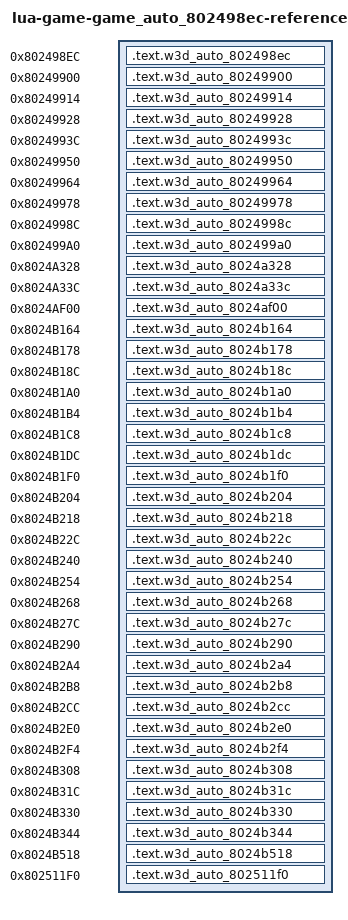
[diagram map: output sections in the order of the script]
/* Generated reference-only placements. All bodies are source-built. */
OUTPUT_FORMAT("elf32-powerpc")
OUTPUT_ARCH(powerpc)
ENTRY(w3d_auto_802498ec)
_SDA_BASE_ = 0x804b2540;
_SDA2_BASE_ = 0x804c2540;
SECTIONS {
  .text.w3d_auto_802498ec 0x802498ec : { *(.text.w3d_auto_802498ec) }
  .text.w3d_auto_80249900 0x80249900 : { *(.text.w3d_auto_80249900) }
  .text.w3d_auto_80249914 0x80249914 : { *(.text.w3d_auto_80249914) }
  .text.w3d_auto_80249928 0x80249928 : { *(.text.w3d_auto_80249928) }
  .text.w3d_auto_8024993c 0x8024993c : { *(.text.w3d_auto_8024993c) }
  .text.w3d_auto_80249950 0x80249950 : { *(.text.w3d_auto_80249950) }
  .text.w3d_auto_80249964 0x80249964 : { *(.text.w3d_auto_80249964) }
  .text.w3d_auto_80249978 0x80249978 : { *(.text.w3d_auto_80249978) }
  .text.w3d_auto_8024998c 0x8024998c : { *(.text.w3d_auto_8024998c) }
  .text.w3d_auto_802499a0 0x802499a0 : { *(.text.w3d_auto_802499a0) }
  .text.w3d_auto_8024a328 0x8024a328 : { *(.text.w3d_auto_8024a328) }
  .text.w3d_auto_8024a33c 0x8024a33c : { *(.text.w3d_auto_8024a33c) }
  .text.w3d_auto_8024af00 0x8024af00 : { *(.text.w3d_auto_8024af00) }
  .text.w3d_auto_8024b164 0x8024b164 : { *(.text.w3d_auto_8024b164) }
  .text.w3d_auto_8024b178 0x8024b178 : { *(.text.w3d_auto_8024b178) }
  .text.w3d_auto_8024b18c 0x8024b18c : { *(.text.w3d_auto_8024b18c) }
  .text.w3d_auto_8024b1a0 0x8024b1a0 : { *(.text.w3d_auto_8024b1a0) }
  .text.w3d_auto_8024b1b4 0x8024b1b4 : { *(.text.w3d_auto_8024b1b4) }
  .text.w3d_auto_8024b1c8 0x8024b1c8 : { *(.text.w3d_auto_8024b1c8) }
  .text.w3d_auto_8024b1dc 0x8024b1dc : { *(.text.w3d_auto_8024b1dc) }
  .text.w3d_auto_8024b1f0 0x8024b1f0 : { *(.text.w3d_auto_8024b1f0) }
  .text.w3d_auto_8024b204 0x8024b204 : { *(.text.w3d_auto_8024b204) }
  .text.w3d_auto_8024b218 0x8024b218 : { *(.text.w3d_auto_8024b218) }
  .text.w3d_auto_8024b22c 0x8024b22c : { *(.text.w3d_auto_8024b22c) }
  .text.w3d_auto_8024b240 0x8024b240 : { *(.text.w3d_auto_8024b240) }
  .text.w3d_auto_8024b254 0x8024b254 : { *(.text.w3d_auto_8024b254) }
  .text.w3d_auto_8024b268 0x8024b268 : { *(.text.w3d_auto_8024b268) }
  .text.w3d_auto_8024b27c 0x8024b27c : { *(.text.w3d_auto_8024b27c) }
  .text.w3d_auto_8024b290 0x8024b290 : { *(.text.w3d_auto_8024b290) }
  .text.w3d_auto_8024b2a4 0x8024b2a4 : { *(.text.w3d_auto_8024b2a4) }
  .text.w3d_auto_8024b2b8 0x8024b2b8 : { *(.text.w3d_auto_8024b2b8) }
  .text.w3d_auto_8024b2cc 0x8024b2cc : { *(.text.w3d_auto_8024b2cc) }
  .text.w3d_auto_8024b2e0 0x8024b2e0 : { *(.text.w3d_auto_8024b2e0) }
  .text.w3d_auto_8024b2f4 0x8024b2f4 : { *(.text.w3d_auto_8024b2f4) }
  .text.w3d_auto_8024b308 0x8024b308 : { *(.text.w3d_auto_8024b308) }
  .text.w3d_auto_8024b31c 0x8024b31c : { *(.text.w3d_auto_8024b31c) }
  .text.w3d_auto_8024b330 0x8024b330 : { *(.text.w3d_auto_8024b330) }
  .text.w3d_auto_8024b344 0x8024b344 : { *(.text.w3d_auto_8024b344) }
  .text.w3d_auto_8024b518 0x8024b518 : { *(.text.w3d_auto_8024b518) }
  .text.w3d_auto_802511f0 0x802511f0 : { *(.text.w3d_auto_802511f0) }
  /DISCARD/ : { *(.text*) *(.rodata*) *(.data*) *(.bss*) *(.sdata*) *(.sbss*) *(.comment) }
}
